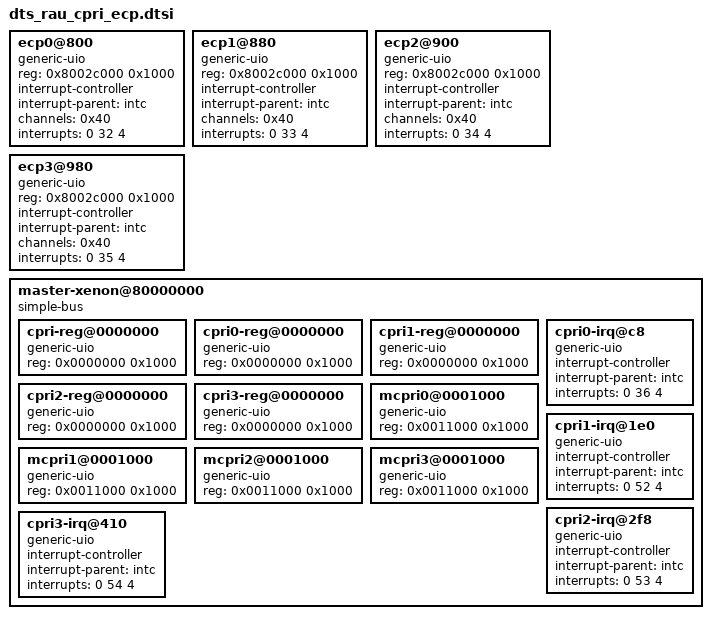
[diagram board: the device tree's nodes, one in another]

	ecp0@800 {
		compatible = "generic-uio";
		reg = < 0x8002c000 0x1000 >;
		interrupt-controller;
		interrupt-parent = <&intc>;
		channels = < 0x40 >;
		interrupts = < 0 32 4 >;
	};

	ecp1@880 {
		compatible = "generic-uio";
		reg = < 0x8002c000 0x1000 >;
		interrupt-controller;
		interrupt-parent = <&intc>;
		channels = < 0x40 >;
		interrupts = < 0 33 4 >;
	};

	ecp2@900 {
		compatible = "generic-uio";
		reg = < 0x8002c000 0x1000 >;
		interrupt-controller;
		interrupt-parent = <&intc>;
		channels = < 0x40 >;
		interrupts = < 0 34 4 >;
	};

	ecp3@980 {
		compatible = "generic-uio";
		reg = < 0x8002c000 0x1000 >;
		interrupt-controller;
		interrupt-parent = <&intc>;
		channels = < 0x40 >;
		interrupts = < 0 35 4 >;
	};

	master-xenon@80000000 {
		compatible = "simple-bus";
		ranges = < 0x0000000 0x80000000 0x10000000 >;
		#address-cells = < 0x01 >;
		#size-cells = < 0x01 >;

		cpri-reg@0000000 {
			compatible = "generic-uio";
			reg = < 0x0000000 0x1000 >;
		};

		cpri0-reg@0000000 {
			compatible = "generic-uio";
			reg = < 0x0000000 0x1000 >;
		};

		cpri1-reg@0000000 {
			compatible = "generic-uio";
			reg = < 0x0000000 0x1000 >;
		};

		cpri2-reg@0000000 {
			compatible = "generic-uio";
			reg = < 0x0000000 0x1000 >;
		};

		cpri3-reg@0000000 {
			compatible = "generic-uio";
			reg = < 0x0000000 0x1000 >;
		};

		mcpri0@0001000 {
			compatible = "generic-uio";
			reg = < 0x0011000 0x1000 >;
		};

		mcpri1@0001000 {
			compatible = "generic-uio";
			reg = < 0x0011000 0x1000 >;
		};

		mcpri2@0001000 {
			compatible = "generic-uio";
			reg = < 0x0011000 0x1000 >;
		};

		mcpri3@0001000 {
			compatible = "generic-uio";
			reg = < 0x0011000 0x1000 >;
		};

		cpri0-irq@c8 {
			compatible = "generic-uio";
			interrupt-controller;
			interrupt-parent = <&intc>;
			interrupts = < 0 36 4 >;
		};

		cpri1-irq@1e0 {
			compatible = "generic-uio";
			interrupt-controller;
			interrupt-parent = <&intc>;
			interrupts = < 0 52 4 >;
		};

		cpri2-irq@2f8 {
			compatible = "generic-uio";
			interrupt-controller;
			interrupt-parent = <&intc>;
			interrupts = < 0 53 4 >;
		};

		cpri3-irq@410 {
			compatible = "generic-uio";
			interrupt-controller;
			interrupt-parent = <&intc>;
			interrupts = < 0 54 4 >;
		};

	};

